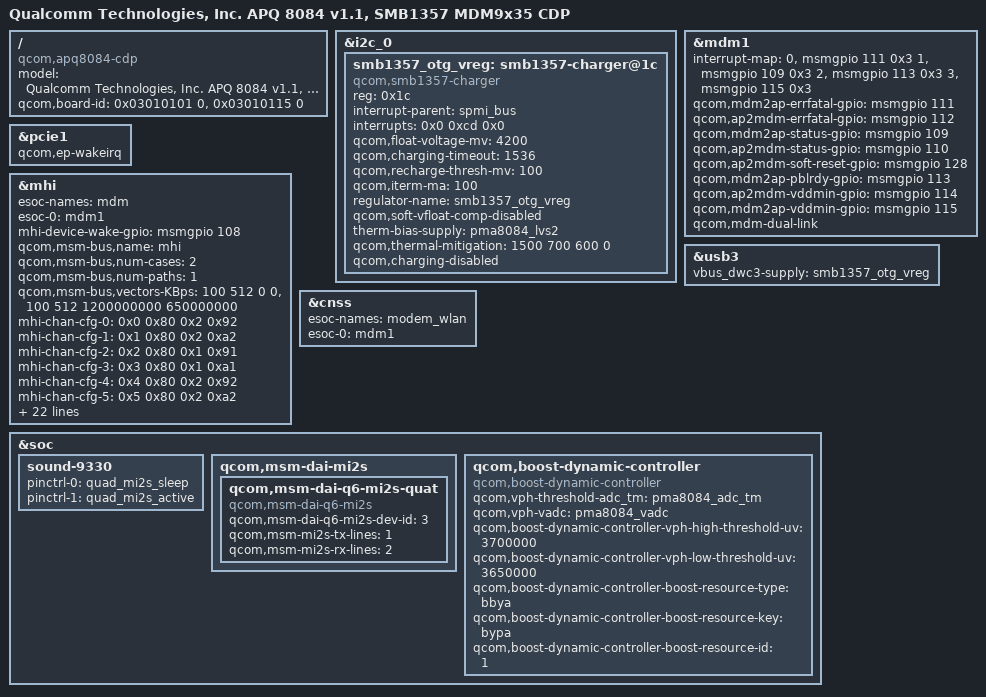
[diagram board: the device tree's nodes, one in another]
/* Copyright (c) 2013-2015, The Linux Foundation. All rights reserved.
 *
 * This program is free software; you can redistribute it and/or modify
 * it under the terms of the GNU General Public License version 2 and
 * only version 2 as published by the Free Software Foundation.
 *
 * This program is distributed in the hope that it will be useful,
 * but WITHOUT ANY WARRANTY; without even the implied warranty of
 * MERCHANTABILITY or FITNESS FOR A PARTICULAR PURPOSE.  See the
 * GNU General Public License for more details.
 */

/dts-v1/;

#include "apq8084-v1.1.dtsi"
#include "apq8084-cdp.dtsi"

/ {
	model = "Qualcomm Technologies, Inc. APQ 8084 v1.1, SMB1357 MDM9x35 CDP";
	compatible = "qcom,apq8084-cdp", "qcom,apq8084", "qcom,cdp";
	qcom,board-id = <0x03010101 0>,
			<0x03010115 0>;
};

&i2c_0 {
	smb1357_otg_vreg: smb1357-charger@1c {
		compatible = "qcom,smb1357-charger";
		reg = <0x1c>;
		interrupt-parent = <&spmi_bus>;
		interrupts = <0x0 0xcd 0x0>;	/* PMA8084 GPIO 14 */
		qcom,float-voltage-mv = <4200>;
		qcom,charging-timeout = <1536>;
		qcom,recharge-thresh-mv = <100>;
		qcom,iterm-ma = <100>;
		regulator-name = "smb1357_otg_vreg";
		qcom,soft-vfloat-comp-disabled;
		therm-bias-supply = <&pma8084_lvs2>;
		qcom,thermal-mitigation = <1500 700 600 0>;
		qcom,charging-disabled;
	};
};

&mdm1 {
	interrupt-map = <0 &msmgpio 111 0x3
			1 &msmgpio 109 0x3
			2 &msmgpio 113 0x3
			3 &msmgpio 115 0x3>;
	qcom,mdm2ap-errfatal-gpio = <&msmgpio 111 0x00>;
	qcom,ap2mdm-errfatal-gpio = <&msmgpio 112 0x00>;
	qcom,mdm2ap-status-gpio   = <&msmgpio 109 0x00>;
	qcom,ap2mdm-status-gpio   = <&msmgpio 110 0x00>;
	qcom,ap2mdm-soft-reset-gpio = <&msmgpio 128 0x00>;
	qcom,mdm2ap-pblrdy-gpio = <&msmgpio 113 0x00>;
	qcom,ap2mdm-vddmin-gpio = <&msmgpio 114 0x00>;
	qcom,mdm2ap-vddmin-gpio = <&msmgpio 115 0x00>;
	qcom,mdm-dual-link;
	status = "ok";
};

&pcie1 {
	qcom,ep-wakeirq;
};

&mhi {
	esoc-names = "mdm";
	esoc-0 = <&mdm1>;
	mhi-device-wake-gpio =
		<&msmgpio 108 0>;
	qcom,msm-bus,name = "mhi";
	qcom,msm-bus,num-cases = <2>;
	qcom,msm-bus,num-paths = <1>;
	qcom,msm-bus,vectors-KBps =
			<100 512 0 0>,
			<100 512 1200000000 650000000>;
	mhi-chan-cfg-0 = <0x0 0x80 0x2 0x92>;
	mhi-chan-cfg-1 = <0x1 0x80 0x2 0xa2>;
	mhi-chan-cfg-2 = <0x2 0x80 0x1 0x91>;
	mhi-chan-cfg-3 = <0x3 0x80 0x1 0xa1>;
	mhi-chan-cfg-4 = <0x4 0x80 0x2 0x92>;
	mhi-chan-cfg-5 = <0x5 0x80 0x2 0xa2>;
	mhi-chan-cfg-6 = <0x6 0xa 0x0 0x92>;
	mhi-chan-cfg-7 = <0x7 0xa 0x0 0xa2>;
	mhi-chan-cfg-10 = <0xa 0x80 0x1 0x92>;
	mhi-chan-cfg-11 = <0xb 0x80 0x1 0xa2>;
	mhi-chan-cfg-14 = <0xe 0x40 0x1 0x92>;
	mhi-chan-cfg-15 = <0xf 0x40 0x1 0xa2>;
	mhi-chan-cfg-16 = <0x10 0x40 0x1 0x92>;
	mhi-chan-cfg-17 = <0x11 0x40 0x1 0xa2>;
	mhi-chan-cfg-18 = <0x12 0x40 0x1 0x92>;
	mhi-chan-cfg-19 = <0x13 0x40 0x1 0xa2>;
	mhi-chan-cfg-20 = <0x14 0xa 0x0 0x92>;
	mhi-chan-cfg-21 = <0x15 0xa 0x0 0xa2>;
	mhi-chan-cfg-32 = <0x20 0x80 0x2 0x92>;
	mhi-chan-cfg-33 = <0x21 0x80 0x2 0xa2>;
	mhi-chan-cfg-100 = <0x64 0x80 0x3 0x52>;
	mhi-chan-cfg-101 = <0x65 0x80 0x4 0x62>;
	mhi-event-rings = <5>;
	mhi-event-cfg-0 = <0x80 0x0 0x1 0x11>;
	mhi-event-cfg-1 = <0x80 0x1 0x1 0x11>;
	mhi-event-cfg-2 = <0x80 0x2 0x5 0x11>;
	mhi-event-cfg-3 = <0x100 0x3 0x1 0x9>;
	mhi-event-cfg-4 = <0x100 0x4 0x1 0x8>;
};

&usb3 {
	vbus_dwc3-supply = <&smb1357_otg_vreg>;
};

&cnss {
	esoc-names = "modem_wlan";
	esoc-0 = <&mdm1>;
};

&soc {
	sound-9330 {
		pinctrl-names = "pmx-quad-mi2s-sleep",
				"pmx-quad-mi2s-active";
		pinctrl-0 = <&quad_mi2s_sleep>;
		pinctrl-1 = <&quad_mi2s_active>;
	};

	qcom,msm-dai-mi2s {
		qcom,msm-dai-q6-mi2s-quat {
			compatible = "qcom,msm-dai-q6-mi2s";
			qcom,msm-dai-q6-mi2s-dev-id = <3>;
			qcom,msm-mi2s-tx-lines = <1>;
			qcom,msm-mi2s-rx-lines = <2>;
		};
	};
	qcom,boost-dynamic-controller {
		compatible = "qcom,boost-dynamic-controller";
		qcom,vph-threshold-adc_tm = <&pma8084_adc_tm>;
		qcom,vph-vadc = <&pma8084_vadc>;
		qcom,boost-dynamic-controller-vph-high-threshold-uv = <3700000>;
		qcom,boost-dynamic-controller-vph-low-threshold-uv = <3650000>;
		qcom,boost-dynamic-controller-boost-resource-type = "bbya";
		qcom,boost-dynamic-controller-boost-resource-key = "bypa";
		qcom,boost-dynamic-controller-boost-resource-id = <1>;
	};
};
